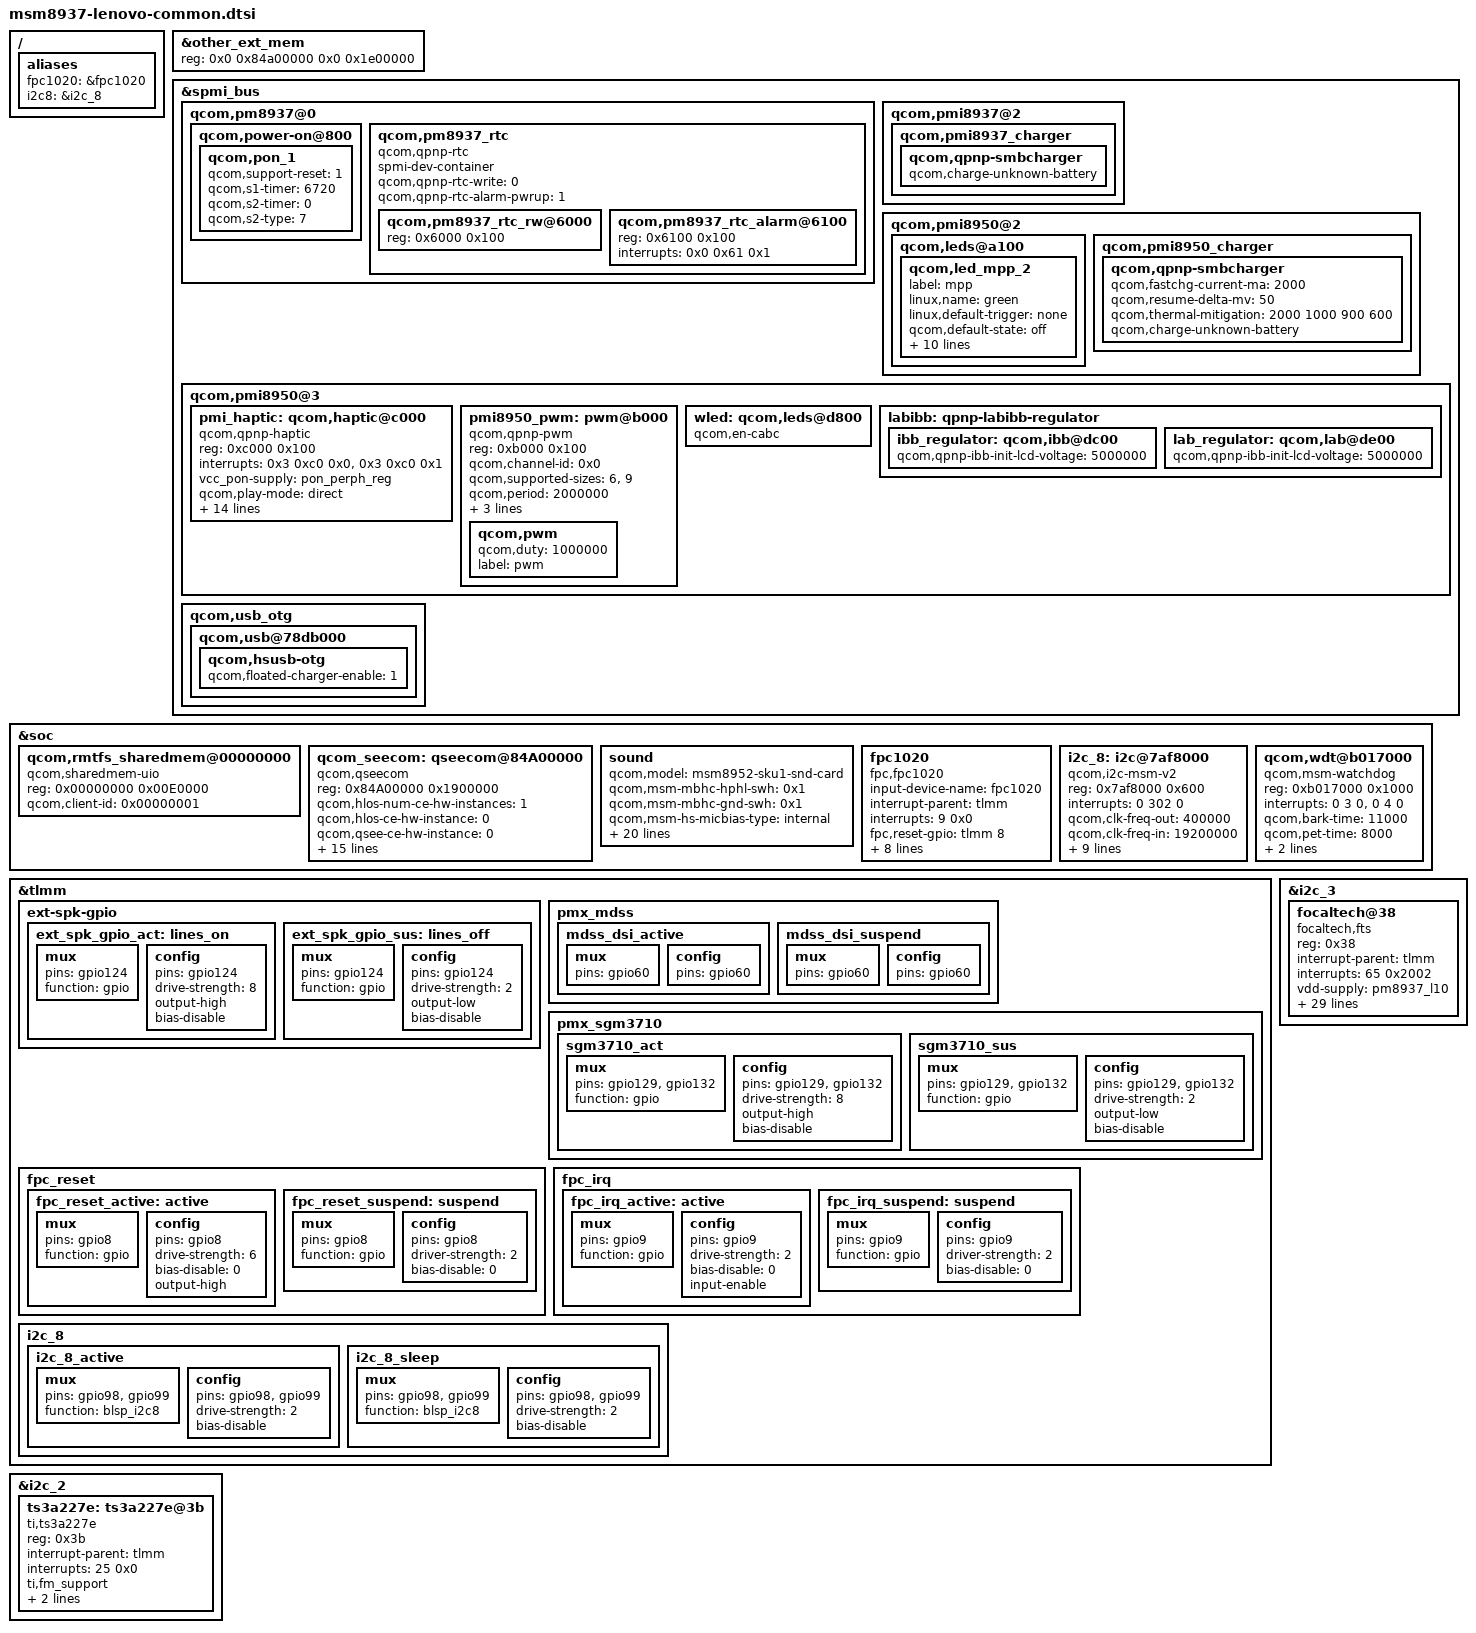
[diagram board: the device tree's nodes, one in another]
/*
 * Copyright (c) 2015, The lenovo mobile Inc. All rights reserved.
 *
 * This program is free software; you can redistribute it and/or modify
 * it under the terms of the GNU General Public License version 2 and
 * only version 2 as published by the Free Software Foundation.
 *
 * This program is distributed in the hope that it will be useful,
 * but WITHOUT ANY WARRANTY; without even the implied warranty of
 * MERCHANTABILITY or FITNESS FOR A PARTICULAR PURPOSE.  See the
 * GNU General Public License for more details.
 */


#include "../msm8937.dtsi"
#include "../msm8937-pmi8950-qrd-sku1.dtsi"

&other_ext_mem {
		reg = <0x0 0x84a00000 0x0 0x1e00000>;
	};


/ {
	aliases {
		fpc1020 = &fpc1020;
                i2c8 = &i2c_8;
	};
};

&spmi_bus {
	qcom,pm8937@0 {
		qcom,power-on@800 {
			qcom,pon_1 {
				qcom,support-reset = <1>;
				qcom,s1-timer = <6720>;
				qcom,s2-timer = <0>;
				qcom,s2-type = <7>;
			};
		};

                qcom,pm8937_rtc {
			spmi-dev-container;
			compatible = "qcom,qpnp-rtc";
			#address-cells = <1>;
			#size-cells = <1>;
			qcom,qpnp-rtc-write = <0>;
			qcom,qpnp-rtc-alarm-pwrup = <1>;

			qcom,pm8937_rtc_rw@6000 {
				reg = <0x6000 0x100>;
			};

			qcom,pm8937_rtc_alarm@6100 {
				reg = <0x6100 0x100>;
				interrupts = <0x0 0x61 0x1>;
			};
		};
	};

	qcom,pmi8937@2 {
                qcom,pmi8937_charger {
                        qcom,qpnp-smbcharger {
                                qcom,charge-unknown-battery;
                        };
                };
        };

	qcom,pmi8950@2 {
		qcom,leds@a100 {
			status = "okay";
			qcom,led_mpp_2 {
                                label = "mpp";
                                linux,name = "green";
                                linux,default-trigger = "none";
                                qcom,default-state = "off";
                                qcom,max-current = <5>;
                                qcom,current-setting = <5>;
                                qcom,id = <6>;
                                qcom,mode = "pwm";
                                qcom,pwm-channel = <0>;
                                pwms = <&pmi8950_pwm 0 0>;
                                pwm-names="green";
                                qcom,source-sel = <8>;
                                qcom,pwm-us=<1000>;
                                qcom,mode-ctrl = <0x60>;
			};
		};
                qcom,pmi8950_charger {
                        qcom,qpnp-smbcharger {
                                qcom,fastchg-current-ma = <2000>;
                                qcom,resume-delta-mv = <50>;
                                qcom,thermal-mitigation = <2000 1000 900 600>;
                                qcom,charge-unknown-battery;
                                /delete-property/ qcom,parallel-usb-min-current-ma;
                                /delete-property/ qcom,parallel-usb-9v-min-current-ma;
                                /delete-property/ qcom,parallel-allowed-lowering-ma;
                        };
                 };
          };

        qcom,pmi8950@3 {
		pmi_haptic: qcom,haptic@c000 {
                                compatible = "qcom,qpnp-haptic";
                                reg = <0xc000 0x100>;
                                interrupts = <0x3 0xc0 0x0>,
                                             <0x3 0xc0 0x1>;
                                interrupt-names = "sc-irq", "play-irq";
                                                   vcc_pon-supply = <&pon_perph_reg>;
                                qcom,play-mode = "direct";
                                qcom,wave-play-rate-us = <5263>;
                                qcom,actuator-type = "erm";
                                qcom,wave-shape = "square";
                                qcom,vmax-mv = <2800>;
                                qcom,ilim-ma = <800>;
                                qcom,sc-deb-cycles = <8>;
                                qcom,int-pwm-freq-khz = <505>;
                                qcom,en-brake;
                                qcom,brake-pattern = [03 03 00 00];
                                qcom,use-play-irq;
                                qcom,use-sc-irq;
                                qcom,wave-samples = [3e 3e 3e 3e 3e 3e 3e 3e];
                                qcom,wave-rep-cnt = <1>;
                                qcom,wave-samp-rep-cnt = <1>;
		};

                pmi8950_pwm: pwm@b000{
                                status = "okay";
                                compatible = "qcom,qpnp-pwm";
                                reg = <0xb000 0x100>;
                                reg-names = "qpnp-lpg-channel-base";
                                qcom,channel-id = <0x0>;
                                qcom,supported-sizes = <6>,<9>;
                                qcom,period = <2000000>;
                                qcom,mode-select=<0>;
                                qcom,dtest-output = <1>;
                                qcom,dtest-line = <1>;
                                #pwm-cells = <2>;
                                qcom,pwm{
                                         qcom,duty = <1000000>;
                                         label = "pwm";
                       };
                };

                wled: qcom,leds@d800 {
                                qcom,en-cabc;
                                /delete-property/qcom,en-ext-pfet-sc-pro;
                };

		labibb: qpnp-labibb-regulator {
			ibb_regulator: qcom,ibb@dc00 {
				/delete-property/
					qcom,qpnp-ibb-use-default-voltage;
				qcom,qpnp-ibb-init-lcd-voltage = <5000000>;
			};

	                lab_regulator: qcom,lab@de00 {
				/delete-property/
					qcom,qpnp-ibb-use-default-voltage;
				qcom,qpnp-ibb-init-lcd-voltage = <5000000>;
			};
		};
	};

        qcom,usb_otg {
                qcom,usb@78db000 {
                        qcom,hsusb-otg {
                                qcom,floated-charger-enable = <1>;
                        };
                 };
          };
};

&soc {
	qcom,rmtfs_sharedmem@00000000 {
		compatible = "qcom,sharedmem-uio";
		reg = <0x00000000 0x00E0000>;
		reg-names = "rmtfs";
		qcom,client-id = <0x00000001>;
	};

	/delete-node/ qseecom@85b00000;

	qcom_seecom: qseecom@84A00000 {
		compatible = "qcom,qseecom";
		reg = <0x84A00000 0x1900000>;
		reg-names = "secapp-region";
		qcom,hlos-num-ce-hw-instances = <1>;
		qcom,hlos-ce-hw-instance = <0>;
		qcom,qsee-ce-hw-instance = <0>;
		qcom,disk-encrypt-pipe-pair = <2>;
		qcom,support-fde;
		qcom,appsbl-qseecom-support;
		qcom,msm-bus,name = "qseecom-noc";
		qcom,msm-bus,num-cases = <4>;
		qcom,msm-bus,num-paths = <1>;
		qcom,support-bus-scaling;
		qcom,msm-bus,vectors-KBps =
			<55 512 0 0>,
			<55 512 0 0>,
			<55 512 120000 1200000>,
			<55 512 393600 3936000>;
		clocks = <&clock_gcc clk_crypto_clk_src>,
			 <&clock_gcc clk_gcc_crypto_clk>,
			 <&clock_gcc clk_gcc_crypto_ahb_clk>,
			 <&clock_gcc clk_gcc_crypto_axi_clk>;
		clock-names = "core_clk_src", "core_clk",
				"iface_clk", "bus_clk";
		qcom,ce-opp-freq = <100000000>;
	};

	sound {
		qcom,model = "msm8952-sku1-snd-card";
		qcom,msm-mbhc-hphl-swh = <0x1>;
		qcom,msm-mbhc-gnd-swh = <0x1>;
		qcom,msm-hs-micbias-type = "internal";
		qcom,msm-spk-ext-pa = <&tlmm 124 0>;
		qcom,msm-hs-ext-rbias;
		qcom,msm-gpios =
			"pri_i2s",
			"ext_spk_gpio";
		qcom,pinctrl-names =
			"all_off",
			"pri_i2s_act",
			"ext_spk_gpio_act",
			"pri_i2s_ext_spk_act";
		pinctrl-names =
			"all_off",
			"pri_i2s_act",
			"ext_spk_gpio_act",
			"pri_i2s_ext_spk_act";
		pinctrl-0 = <&cdc_pdm_lines_sus
				&cdc_pdm_lines_2_sus &ext_spk_gpio_sus>;
		pinctrl-1 = <&cdc_pdm_lines_act
				&cdc_pdm_lines_2_act &ext_spk_gpio_sus>;
		pinctrl-2 = <&cdc_pdm_lines_sus
				&cdc_pdm_lines_2_sus &ext_spk_gpio_act>;
		pinctrl-3 = <&cdc_pdm_lines_act
				&cdc_pdm_lines_2_act &ext_spk_gpio_act>;
		qcom,audio-routing =
			"RX_BIAS", "MCLK",
			"SPK_RX_BIAS", "MCLK",
			"INT_LDO_H", "MCLK",
			"MIC BIAS External", "Handset Mic",
			"MIC BIAS Internal2", "Headset Mic",
			"MIC BIAS External", "Secondary Mic",
			"AMIC1", "MIC BIAS External",
			"AMIC2", "MIC BIAS Internal2",
			"AMIC3", "MIC BIAS External";
	};

	fpc1020: fpc1020 {
		status = "ok";
		compatible = "fpc,fpc1020";
		input-device-name = "fpc1020";
		interrupt-parent = <&tlmm>;
		interrupts = <9 0x0>;
		fpc,reset-gpio  = <&tlmm 8 0x2>;
		fpc,irq-gpio    = <&tlmm 9 0x1>;
		pinctrl-names = "pmx_fp_active", "pmx_fp_suspend";
		pinctrl-0 = <&fpc_reset_active &fpc_irq_active>;
		pinctrl-1 = <&fpc_reset_suspend &fpc_irq_suspend>;

		vcc_spi-supply  = <&pm8937_l5>;
		vdd_ana-supply  = <&pm8937_l5>;
		vdd_io-supply   = <&pm8937_l5>;
		/* fpc,enable-on-boot; */
		clock-names = "iface_clk", "core_clk";
		clocks = <&clock_gcc clk_gcc_blsp2_ahb_clk>,
			<&clock_gcc clk_gcc_blsp2_qup2_spi_apps_clk>;
	};

	i2c_8: i2c@7af8000 { /* BLSP2 QUP4 */
		compatible = "qcom,i2c-msm-v2";
		#address-cells = <1>;
		#size-cells = <0>;
		reg-names = "qup_phys_addr";
		reg = <0x7af8000 0x600>;
		interrupt-names = "qup_irq";
		interrupts = <0 302 0>;
		qcom,clk-freq-out = <400000>;
		qcom,clk-freq-in  = <19200000>;
		clock-names = "iface_clk", "core_clk";
		clocks = <&clock_gcc clk_gcc_blsp2_ahb_clk>,
			 <&clock_gcc clk_gcc_blsp2_qup4_i2c_apps_clk>;

		pinctrl-names = "i2c_active", "i2c_sleep";
		pinctrl-0 = <&i2c_8_active>;
		pinctrl-1 = <&i2c_8_sleep>;
		qcom,noise-rjct-scl = <0>;
		qcom,noise-rjct-sda = <0>;
		qcom,master-id = <84>;
		dmas = <&dma_blsp2 10 64 0x20000020 0x20>,
			<&dma_blsp2 11 32 0x20000020 0x20>;
		dma-names = "tx", "rx";
                };

	qcom,wdt@b017000 {
		compatible = "qcom,msm-watchdog";
		reg = <0xb017000 0x1000>;
		reg-names = "wdt-base";
		interrupts = <0 3 0>, <0 4 0>;
		qcom,bark-time = <11000>;
		qcom,pet-time = <8000>;
		qcom,ipi-ping;
		qcom,wakeup-enable;
		status = "okay";
                };
	};

&tlmm {
	ext-spk-gpio {
		ext_spk_gpio_act: lines_on {
			mux {
				pins = "gpio124";
				function = "gpio";
			};

			config {
				pins = "gpio124";
				drive-strength = <8>;
				output-high;
				bias-disable;
			};
		};

		ext_spk_gpio_sus: lines_off {
			mux {
				pins = "gpio124";
				function = "gpio";
			};

			config {
				pins = "gpio124";
				drive-strength = <2>;
				output-low;
				bias-disable;
			};
		};
	};

	pmx_mdss: pmx_mdss {
		mdss_dsi_active: mdss_dsi_active {
			mux {
				pins = "gpio60";
			};
			config {
				pins = "gpio60";
			};
		};
		mdss_dsi_suspend: mdss_dsi_suspend {
			mux {
				pins = "gpio60";
			};
			config {
				pins = "gpio60";
			};
                };
        };

	pmx_sgm3710 {
		sgm3710_act: sgm3710_act {
			mux {
				pins = "gpio129", "gpio132";
				function = "gpio";
			};

			config {
				pins = "gpio129", "gpio132";
				drive-strength = <8>;
				output-high;
				bias-disable;
			};
		};

		sgm3710_sus: sgm3710_sus {
			mux {
				pins = "gpio129", "gpio132";
				function = "gpio";
			};

			config {
				pins = "gpio129", "gpio132";
				drive-strength = <2>;
				output-low;
				bias-disable;
			};
		};
	};
};

&i2c_2 {
	ts3a227e: ts3a227e@3b {
		compatible = "ti,ts3a227e";
		reg = <0x3b>;
		interrupt-parent = <&tlmm>;
		interrupts = <25 0x0>;
		ti,fm_support;
		pinctrl-names = "pmx_hp_switch_on",
			"pmx_hp_switch_off";
		pinctrl-0 = <&sgm3710_act>;
		pinctrl-1 = <&sgm3710_sus>;
	};
};

&i2c_3 {
	status = "ok";
	focaltech@38 {
		compatible = "focaltech,fts";
		reg = <0x38>;
		interrupt-parent = <&tlmm>;
		interrupts = <65 0x2002>;
		vdd-supply = <&pm8937_l10>;
		vcc_i2c-supply = <&pm8937_l5>;
		/* pins used by touchscreen */
		pinctrl-names = "pmx_ts_active",
				"pmx_ts_suspend",
				"pmx_ts_release";
		pinctrl-0 = <&ts_int_active &ts_reset_active>;
		pinctrl-1 = <&ts_int_suspend &ts_reset_suspend>;
		pinctrl-2 = <&ts_release>;
		focaltech,name = "ft5346i";
		focaltech,family-id = <0x54>;
		focaltech,reset-gpio = <&tlmm 64 0x0>;
		focaltech,irq-gpio = <&tlmm 65 0x1>;
		focaltech,display-coords = <0 0 1080 1920>;
		focaltech,panel-coords = <0 0 1080 1920>;
		focaltech,button-map= <139 172 158>; /* APP_SWITCH HOME BACK */
		focaltech,button-y-coord = <2040>;
		focaltech,button-x-coords = <120 500 900>;
		focaltech,no-force-update;
		focaltech,i2c-pull-up;
		focaltech,group-id = <1>;
		focaltech,hard-reset-delay-ms = <20>;
		focaltech,soft-reset-delay-ms = <200>;
		focaltech,num-max-touches = <10>;
		focaltech,fw-delay-aa-ms = <2>;
		focaltech,fw-delay-55-ms = <2>;
		focaltech,fw-upgrade-id1 = <0x54>;
		focaltech,fw-upgrade-id2 = <0x2c>;
		focaltech,fw-delay-readid-ms = <20>;
		focaltech,fw-delay-era-flsh-ms = <2000>;
		focaltech,fw-auto-cal;
		focaltech,fw-auto-upgrade;
		focaltech,fw-name = "FT_5x46_Ref_V0b_D01_20160513_app.i";
	};
};

&tlmm {
	fpc_reset {
		fpc_reset_active: active {
			mux {
				pins = "gpio8";
				function = "gpio";
			};

			config {
				pins = "gpio8";
				drive-strength = <6>;
				bias-disable = <0>;
				output-high;
			};
		};
		fpc_reset_suspend: suspend {
			mux {
				pins = "gpio8";
				function = "gpio";
			};

			config {
				pins = "gpio8";
				driver-strength = <2>;
				bias-disable = <0>;
			};
		};
	};

	fpc_irq {
		fpc_irq_active: active {
			mux {
				pins = "gpio9";
				function = "gpio";
			};

			config {
				pins = "gpio9";
				drive-strength = <2>;
				bias-disable = <0>;
				input-enable;
			};
		};
		fpc_irq_suspend: suspend {
			mux {
				pins = "gpio9";
				function = "gpio";
			};

			config {
				pins = "gpio9";
				driver-strength = <2>;
				bias-disable = <0>;
			};
		};
	};

        i2c_8 {
                       /* active state */
               i2c_8_active: i2c_8_active{
                       mux {
                               /* CLK, DATA */
                               pins = "gpio98", "gpio99";
                               function = "blsp_i2c8";
                       };

                       config {
                               pins = "gpio98", "gpio99";
                               drive-strength = <2>; /* 2 MA */
                               bias-disable; /* No PULL */
                       };
               };

                       /* suspended state */
               i2c_8_sleep: i2c_8_sleep {
                       mux {
                               /* CLK, DATA */
                               pins = "gpio98", "gpio99";
                               function = "blsp_i2c8";
                       };

                       config {
                               pins = "gpio98", "gpio99";
                               drive-strength = <2>; /* 2 MA */
                               bias-disable; /* No PULL */
                       };
               };
       };
};
